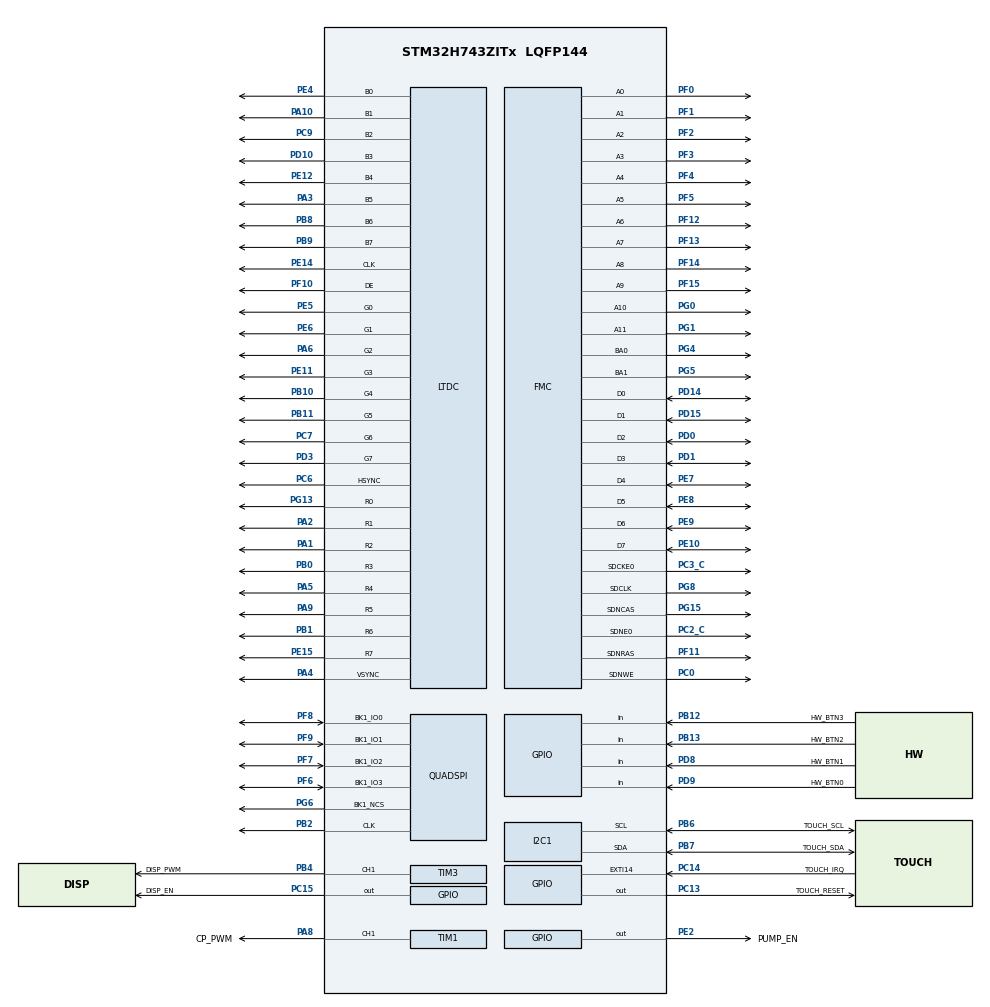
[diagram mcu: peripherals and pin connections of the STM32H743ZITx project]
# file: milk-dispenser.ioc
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CORTEX_M7.AccessPermission-Cortex_Memory_Protection_Unit_Region0_Settings=MPU_REGION_FULL_ACCESS
CORTEX_M7.AccessPermission-Cortex_Memory_Protection_Unit_Region1_Settings=MPU_REGION_FULL_ACCESS
CORTEX_M7.BaseAddress-Cortex_Memory_Protection_Unit_Region0_Settings=0x60000000
CORTEX_M7.BaseAddress-Cortex_Memory_Protection_Unit_Region1_Settings=0x30000000
CORTEX_M7.CPU_DCache=Enabled
CORTEX_M7.CPU_ICache=Enabled
CORTEX_M7.DisableExec-Cortex_Memory_Protection_Unit_Region0_Settings=MPU_INSTRUCTION_ACCESS_DISABLE
CORTEX_M7.DisableExec-Cortex_Memory_Protection_Unit_Region1_Settings=MPU_INSTRUCTION_ACCESS_DISABLE
CORTEX_M7.Enable-Cortex_Memory_Protection_Unit_Region0_Settings=MPU_REGION_ENABLE
CORTEX_M7.Enable-Cortex_Memory_Protection_Unit_Region1_Settings=MPU_REGION_ENABLE
CORTEX_M7.IsBufferable-Cortex_Memory_Protection_Unit_Region0_Settings=MPU_ACCESS_NOT_BUFFERABLE
CORTEX_M7.IsCacheable-Cortex_Memory_Protection_Unit_Region0_Settings=MPU_ACCESS_NOT_CACHEABLE
CORTEX_M7.IsCacheable-Cortex_Memory_Protection_Unit_Region1_Settings=MPU_ACCESS_CACHEABLE
CORTEX_M7.IsShareable-Cortex_Memory_Protection_Unit_Region0_Settings=MPU_ACCESS_SHAREABLE
CORTEX_M7.IsShareable-Cortex_Memory_Protection_Unit_Region1_Settings=MPU_ACCESS_NOT_SHAREABLE
CORTEX_M7.MPU_Control=MPU_PRIVILEGED_DEFAULT
CORTEX_M7.Size-Cortex_Memory_Protection_Unit_Region0_Settings=MPU_REGION_SIZE_16MB
CORTEX_M7.Size-Cortex_Memory_Protection_Unit_Region1_Settings=MPU_REGION_SIZE_128KB
DMA2D.ColorMode=DMA2D_OUTPUT_RGB565
FATFS._FS_LOCK=0
FATFS._FS_MINIMIZE=0
FATFS._MAX_SS=4096
FATFS._MIN_SS=4096
FATFS._USE_FASTSEEK=0
FATFS._USE_MKFS=0
FATFS._USE_STRFUNC=0
FMC.BankMapConfig=FMC_SWAPBMAP_SDRAM_SRAM
FMC.CASLatency1=FMC_SDRAM_CAS_LATENCY_2
FMC.ColumnBitsNumber1=FMC_SDRAM_COLUMN_BITS_NUM_10
FMC.ExitSelfRefreshDelay1=8
FMC.LoadToActiveDelay1=2
FMC.RCDDelay1=2
FMC.RPDelay1=2
FMC.RPDelay2=2
FMC.ReadBurst1=FMC_SDRAM_RBURST_ENABLE
FMC.ReadBurst2=FMC_SDRAM_RBURST_ENABLE
FMC.ReadPipeDelay1=FMC_SDRAM_RPIPE_DELAY_0
FMC.RowCycleDelay1=6
FMC.RowCycleDelay2=6
FMC.SDClockPeriod1=FMC_SDRAM_CLOCK_PERIOD_2
FMC.SelfRefreshTime1=5
FMC.WriteRecoveryTime1=3
I2C1.I2C_Fall_Time=14
I2C1.I2C_Rise_Time=14
I2C1.Speed=100
I2C1.Timing=0x108083B5
LTDC.ActiveW=800
LTDC.Alpha0_L0=0
LTDC.Alpha_L0=255
LTDC.BlendingFactor1_L0=LTDC_BLENDING_FACTOR1_PAxCA
LTDC.BlendingFactor2_L0=LTDC_BLENDING_FACTOR2_PAxCA
LTDC.Blue=0
LTDC.Green=0
LTDC.HBP=46
LTDC.HFP=4
LTDC.HSync=30
LTDC.ImageHeight_L0=480
LTDC.ImageWidth_L0=800
LTDC.Layers=0
LTDC.PCPolarity=LTDC_PCPOLARITY_IIPC
LTDC.PixelFormat_L0=LTDC_PIXEL_FORMAT_RGB565
LTDC.Red=0
LTDC.VBP=23
LTDC.VFP=22
LTDC.VSync=10
LTDC.WindowX0_L0=0
LTDC.WindowX1_L0=800
LTDC.WindowY0_L0=0
LTDC.WindowY1_L0=480
Mcu.Family=STM32H7
Mcu.Name=STM32H743ZITx
Mcu.Package=LQFP144
NVIC.EXTI15_10_IRQn=true\:2\:0\:true\:false\:true\:true\:true
NVIC.PriorityGroup=NVIC_PRIORITYGROUP_4
PA1.GPIO_Speed=GPIO_SPEED_FREQ_VERY_HIGH
PA1.Mode=RGB888
PA1.Signal=LTDC_R2
PA10.GPIO_Speed=GPIO_SPEED_FREQ_VERY_HIGH
PA10.Mode=RGB888
PA10.Signal=LTDC_B1
PA13\ (JTMS/SWDIO).Mode=Serial_Wire
PA13\ (JTMS/SWDIO).Signal=DEBUG_JTMS-SWDIO
PA14\ (JTCK/SWCLK).Mode=Serial_Wire
PA14\ (JTCK/SWCLK).Signal=DEBUG_JTCK-SWCLK
PA2.GPIO_Speed=GPIO_SPEED_FREQ_VERY_HIGH
PA2.Mode=RGB888
PA2.Signal=LTDC_R1
PA3.GPIO_Speed=GPIO_SPEED_FREQ_VERY_HIGH
PA3.Mode=RGB888
PA3.Signal=LTDC_B5
PA4.GPIO_Speed=GPIO_SPEED_FREQ_VERY_HIGH
PA4.Mode=RGB888
PA4.Signal=LTDC_VSYNC
PA5.GPIO_Speed=GPIO_SPEED_FREQ_VERY_HIGH
PA5.Mode=RGB888
PA5.Signal=LTDC_R4
PA6.GPIO_Speed=GPIO_SPEED_FREQ_VERY_HIGH
PA6.Mode=RGB888
PA6.Signal=LTDC_G2
PA8.GPIO_Label=CP_PWM
PA8.Signal=S_TIM1_CH1
PA9.GPIO_Speed=GPIO_SPEED_FREQ_VERY_HIGH
PA9.Mode=RGB888
PA9.Signal=LTDC_R5
PB0.GPIO_Speed=GPIO_SPEED_FREQ_VERY_HIGH
PB0.Mode=RGB888
PB0.Signal=LTDC_R3
PB1.GPIO_Speed=GPIO_SPEED_FREQ_VERY_HIGH
PB1.Mode=RGB888
PB1.Signal=LTDC_R6
PB10.GPIO_Speed=GPIO_SPEED_FREQ_VERY_HIGH
PB10.Mode=RGB888
PB10.Signal=LTDC_G4
PB11.GPIO_Speed=GPIO_SPEED_FREQ_VERY_HIGH
PB11.Mode=RGB888
PB11.Signal=LTDC_G5
PB12.GPIO_Label=HW_BTN3
PB12.GPIO_PuPd=GPIO_PULLUP
PB12.Signal=GPIO_Input
PB13.GPIO_Label=HW_BTN2
PB13.GPIO_PuPd=GPIO_PULLUP
PB13.Signal=GPIO_Input
PB2.GPIO_Speed=GPIO_SPEED_FREQ_VERY_HIGH
PB2.Mode=Single Bank 1
PB2.Signal=QUADSPI_CLK
PB4\ (NJTRST).GPIO_Label=DISP_PWM
PB4\ (NJTRST).GPIO_Speed=GPIO_SPEED_FREQ_HIGH
PB4\ (NJTRST).Signal=S_TIM3_CH1
PB6.GPIO_FM6=SYSCFG_PMCR_I2C_PB6_FMP
PB6.GPIO_Label=TOUCH_SCL
PB6.GPIO_PuPd=GPIO_PULLUP
PB6.GPIO_Speed=GPIO_SPEED_FREQ_VERY_HIGH
PB6.Mode=I2C
PB6.Signal=I2C1_SCL
PB7.GPIO_FM7=SYSCFG_PMCR_I2C_PB7_FMP
PB7.GPIO_Label=TOUCH_SDA
PB7.GPIO_PuPd=GPIO_PULLUP
PB7.GPIO_Speed=GPIO_SPEED_FREQ_VERY_HIGH
PB7.Mode=I2C
PB7.Signal=I2C1_SDA
PB8.GPIO_Speed=GPIO_SPEED_FREQ_VERY_HIGH
PB8.Mode=RGB888
PB8.Signal=LTDC_B6
PB9.GPIO_Speed=GPIO_SPEED_FREQ_VERY_HIGH
PB9.Mode=RGB888
PB9.Signal=LTDC_B7
PC0.Signal=FMC_SDNWE
PC13.GPIO_Label=TOUCH_RESET
PC13.GPIO_PuPd=GPIO_PULLUP
PC13.PinState=GPIO_PIN_RESET
PC13.Signal=GPIO_Output
PC14-OSC32_IN\ (OSC32_IN).GPIO_Label=TOUCH_IRQ
PC14-OSC32_IN\ (OSC32_IN).Signal=GPXTI14
PC15-OSC32_OUT\ (OSC32_OUT).GPIO_Label=DISP_EN
PC15-OSC32_OUT\ (OSC32_OUT).Signal=GPIO_Output
PC2_C.Mode=SdramChipSelect1_1
PC2_C.Signal=FMC_SDNE0
PC3_C.Mode=SdramChipSelect1_1
PC3_C.Signal=FMC_SDCKE0
PC6.GPIO_Speed=GPIO_SPEED_FREQ_VERY_HIGH
PC6.Mode=RGB888
PC6.Signal=LTDC_HSYNC
PC7.GPIO_Speed=GPIO_SPEED_FREQ_VERY_HIGH
PC7.Mode=RGB888
PC7.Signal=LTDC_G6
PC9.GPIO_Speed=GPIO_SPEED_FREQ_VERY_HIGH
PC9.Mode=RGB888
PC9.Signal=LTDC_B2
PD0.Signal=FMC_D2_DA2
PD1.Signal=FMC_D3_DA3
PD10.GPIO_Speed=GPIO_SPEED_FREQ_VERY_HIGH
PD10.Mode=RGB888
PD10.Signal=LTDC_B3
PD14.Signal=FMC_D0_DA0
PD15.Signal=FMC_D1_DA1
PD3.GPIO_Speed=GPIO_SPEED_FREQ_VERY_HIGH
PD3.Mode=RGB888
PD3.Signal=LTDC_G7
PD8.GPIO_Label=HW_BTN1
PD8.GPIO_PuPd=GPIO_PULLUP
PD8.Signal=GPIO_Input
PD9.GPIO_Label=HW_BTN0
PD9.GPIO_PuPd=GPIO_PULLUP
PD9.Signal=GPIO_Input
PE0.Signal=FMC_NBL0
PE10.Signal=FMC_D7_DA7
PE11.GPIO_Speed=GPIO_SPEED_FREQ_VERY_HIGH
PE11.Mode=RGB888
PE11.Signal=LTDC_G3
PE12.GPIO_Speed=GPIO_SPEED_FREQ_VERY_HIGH
PE12.Mode=RGB888
PE12.Signal=LTDC_B4
PE14.GPIO_Speed=GPIO_SPEED_FREQ_VERY_HIGH
PE14.Mode=RGB888
PE14.Signal=LTDC_CLK
PE15.GPIO_Speed=GPIO_SPEED_FREQ_VERY_HIGH
PE15.Mode=RGB888
PE15.Signal=LTDC_R7
PE2.GPIO_Label=PUMP_EN
PE2.Signal=GPIO_Output
PE4.GPIO_Speed=GPIO_SPEED_FREQ_VERY_HIGH
PE4.Mode=RGB888
PE4.Signal=LTDC_B0
PE5.GPIO_Speed=GPIO_SPEED_FREQ_VERY_HIGH
PE5.Mode=RGB888
PE5.Signal=LTDC_G0
PE6.GPIO_Speed=GPIO_SPEED_FREQ_VERY_HIGH
PE6.Mode=RGB888
PE6.Signal=LTDC_G1
PE7.Signal=FMC_D4_DA4
PE8.Signal=FMC_D5_DA5
PE9.Signal=FMC_D6_DA6
PF0.Signal=FMC_A0
PF1.Signal=FMC_A1
PF10.GPIO_Speed=GPIO_SPEED_FREQ_VERY_HIGH
PF10.Mode=RGB888
PF10.Signal=LTDC_DE
PF11.Signal=FMC_SDNRAS
PF12.Signal=FMC_A6
PF13.Signal=FMC_A7
PF14.Signal=FMC_A8
PF15.Signal=FMC_A9
PF2.Signal=FMC_A2
PF3.Signal=FMC_A3
PF4.Signal=FMC_A4
PF5.Signal=FMC_A5
PF6.GPIO_Speed=GPIO_SPEED_FREQ_VERY_HIGH
PF6.Mode=Single Bank 1
PF6.Signal=QUADSPI_BK1_IO3
PF7.GPIO_Speed=GPIO_SPEED_FREQ_VERY_HIGH
PF7.Mode=Single Bank 1
PF7.Signal=QUADSPI_BK1_IO2
PF8.GPIO_Speed=GPIO_SPEED_FREQ_VERY_HIGH
PF8.Mode=Single Bank 1
PF8.Signal=QUADSPI_BK1_IO0
PF9.GPIO_Speed=GPIO_SPEED_FREQ_VERY_HIGH
PF9.Mode=Single Bank 1
PF9.Signal=QUADSPI_BK1_IO1
PG0.Signal=FMC_A10
PG1.Signal=FMC_A11
PG13.GPIO_Speed=GPIO_SPEED_FREQ_VERY_HIGH
PG13.Mode=RGB888
PG13.Signal=LTDC_R0
PG15.Signal=FMC_SDNCAS
PG4.Signal=FMC_A14_BA0
PG5.Signal=FMC_A15_BA1
PG6.GPIO_Speed=GPIO_SPEED_FREQ_VERY_HIGH
PG6.Mode=Single Bank 1
PG6.Signal=QUADSPI_BK1_NCS
PG8.Signal=FMC_SDCLK
PH0-OSC_IN\ (PH0).Mode=HSE-External-Oscillator
PH0-OSC_IN\ (PH0).Signal=RCC_OSC_IN
PH1-OSC_OUT\ (PH1).Mode=HSE-External-Oscillator
PH1-OSC_OUT\ (PH1).Signal=RCC_OSC_OUT
ProjectManager.HeapSize=0x2000
ProjectManager.StackSize=0x4000
ProjectManager.TargetToolchain=STM32CubeIDE
QUADSPI.ChipSelectHighTime=QSPI_CS_HIGH_TIME_2_CYCLE
QUADSPI.ClockPrescaler=7
QUADSPI.FifoThreshold=5
QUADSPI.FlashSize=22
RCC.ADCFreq_Value=300000000
RCC.APB1Freq_Value=120000000
RCC.APB2Freq_Value=120000000
RCC.APB3Freq_Value=120000000
RCC.APB4Freq_Value=120000000
RCC.CKPERSourceSelection=RCC_CLKPSOURCE_CSI
RCC.CortexFreq_Value=480000000
RCC.D1PPRE=RCC_APB3_DIV2
RCC.D2PPRE1=RCC_APB1_DIV2
RCC.D2PPRE2=RCC_APB2_DIV2
RCC.D3PPRE=RCC_APB4_DIV2
RCC.DIVM1=2
RCC.DIVM2=3
RCC.DIVM3=3
RCC.DIVN1=64
RCC.DIVN2=60
RCC.DIVN3=20
RCC.DIVR2=3
RCC.DIVR3=10
RCC.FMCCLockSelection=RCC_FMCCLKSOURCE_PLL2
RCC.HCLKFreq_Value=240000000
RCC.HPRE=RCC_HCLK_DIV2
RCC.HSE_VALUE=30000000
RCC.I2C123CLockSelection=RCC_I2C123CLKSOURCE_HSI
RCC.PLL2FRACN=0
RCC.PLL3FRACN=0
RCC.PLLFRACN=0
RCC.PLLSourceVirtual=RCC_PLLSOURCE_HSE
RCC.ProductRev=revV
RCC.SYSCLKFreq_VALUE=480000000
RCC.SYSCLKSource=RCC_SYSCLKSOURCE_PLLCLK
RCC.USBCLockSelection=RCC_USBCLKSOURCE_HSI48
RCC.USBFreq_Value=48000000
SH.FMC_A0.0=FMC_A0,12b-sda1
SH.FMC_A1.0=FMC_A1,12b-sda1
SH.FMC_A10.0=FMC_A10,12b-sda1
SH.FMC_A11.0=FMC_A11,12b-sda1
SH.FMC_A14_BA0.0=FMC_BA0,FourSdramBanks1
SH.FMC_A15_BA1.0=FMC_BA1,FourSdramBanks1
SH.FMC_A2.0=FMC_A2,12b-sda1
SH.FMC_A3.0=FMC_A3,12b-sda1
SH.FMC_A4.0=FMC_A4,12b-sda1
SH.FMC_A5.0=FMC_A5,12b-sda1
SH.FMC_A6.0=FMC_A6,12b-sda1
SH.FMC_A7.0=FMC_A7,12b-sda1
SH.FMC_A8.0=FMC_A8,12b-sda1
SH.FMC_A9.0=FMC_A9,12b-sda1
SH.FMC_D0_DA0.0=FMC_D0,sd-8b-d1
SH.FMC_D1_DA1.0=FMC_D1,sd-8b-d1
SH.FMC_D2_DA2.0=FMC_D2,sd-8b-d1
SH.FMC_D3_DA3.0=FMC_D3,sd-8b-d1
SH.FMC_D4_DA4.0=FMC_D4,sd-8b-d1
SH.FMC_D5_DA5.0=FMC_D5,sd-8b-d1
SH.FMC_D6_DA6.0=FMC_D6,sd-8b-d1
SH.FMC_D7_DA7.0=FMC_D7,sd-8b-d1
SH.FMC_NBL0.0=FMC_NBL0
SH.FMC_SDCLK.0=FMC_SDCLK,12b-sda1
SH.FMC_SDNCAS.0=FMC_SDNCAS,12b-sda1
SH.FMC_SDNRAS.0=FMC_SDNRAS,12b-sda1
SH.FMC_SDNWE.0=FMC_SDNWE,12b-sda1
SH.S_TIM1_CH1.0=TIM1_CH1,PWM Generation1 CH1
SH.S_TIM3_CH1.0=TIM3_CH1,PWM Generation1 CH1
TIM1.AutoReloadPreload=TIM_AUTORELOAD_PRELOAD_DISABLE
TIM1.Channel-PWM\ Generation1\ CH1=TIM_CHANNEL_1
TIM1.Period=3000
TIM1.Prescaler=0
TIM1.Pulse-PWM\ Generation1\ CH1=1500
TIM3.Channel-PWM\ Generation1\ CH1=TIM_CHANNEL_1
TIM3.Period=1024
TIM3.Pulse-PWM\ Generation1\ CH1=922
VP_DMA2D_VS_DMA2D.Mode=DMA2D_Activate
VP_FATFS_VS_Generic.Mode=User_defined
VP_TIM1_VS_ClockSourceINT.Mode=Internal
VP_TIM3_VS_ClockSourceINT.Mode=Internal
board=custom

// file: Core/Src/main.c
/* USER CODE BEGIN Header */
/**
 ******************************************************************************
 * @file           : main.c
 * @brief          : Main program body
 ******************************************************************************
 * @attention
 *
 * <h2><center>&copy; Copyright (c) 2020 STMicroelectronics.
 * All rights reserved.</center></h2>
 *
 * This software component is licensed by ST under BSD 3-Clause license,
 * the "License"; You may not use this file except in compliance with the
 * License. You may obtain a copy of the License at:
 *                        opensource.org/licenses/BSD-3-Clause
 *
 ******************************************************************************
 */
/* USER CODE END Header */
#include "main.h"
#include "dma2d.h"
#include "fatfs.h"
#include "i2c.h"
#include "ltdc.h"
#include "quadspi.h"
#include "tim.h"
#include "gpio.h"
#include "fmc.h"

/* USER CODE BEGIN Includes */
#include <stdio.h>

#include "gt911.h"
#include "hw_buttons.h"
#include "interface.h"
#include "lvgl.h"
#include "pump.h"
#include "pump_power.h"
#include "sst26_flash.h"
#include "tft.h"

/* USER CODE END Includes */

void SystemClock_Config(void);
static void MPU_Config(void);

/* USER CODE BEGIN 0 */
volatile uint32_t time = 0;
volatile uint32_t period = 0;

static lv_color_t dbbuf[LV_HOR_RES_MAX * LV_VER_RES_MAX / 10];

/* USER CODE END 0 */

int main(void)
{
  /* USER CODE BEGIN 1 */
	SCB->VTOR = 0x08040000;
	__enable_irq();

	HAL_StatusTypeDef status;
  /* USER CODE END 1 */

  /* MPU Configuration--------------------------------------------------------*/
  MPU_Config();

  /* Enable I-Cache---------------------------------------------------------*/
  SCB_EnableICache();

  /* Enable D-Cache---------------------------------------------------------*/
  SCB_EnableDCache();

  /* MCU Configuration--------------------------------------------------------*/

  /* Reset of all peripherals, Initializes the Flash interface and the Systick. */
  HAL_Init();

  /* Configure the system clock */
  SystemClock_Config();

  /* Initialize all configured peripherals */
  MX_GPIO_Init();
  MX_LTDC_Init();
  MX_TIM3_Init();
  MX_FMC_Init();
  MX_I2C1_Init();
  MX_TIM1_Init();
  MX_QUADSPI_Init();
  MX_FATFS_Init();
  MX_DMA2D_Init();
  /* USER CODE BEGIN 2 */
	SST26_config.hqspi = &hqspi;
	SST26_config.timeout = 100;
	status = SST26_init();
	if (HAL_OK != status) {
		HAL_QSPI_GetError(&hqspi);
		HAL_QSPI_GetState(&hqspi);
		while (1)
			;
	}

	FATFS fat;
	f_mount(&fat, "", 1);

	pump_config.port = PUMP_EN_GPIO_Port;
	pump_config.pin = PUMP_EN_Pin;
	pump_init();

	pump_power_config.timer = &htim1;
	pump_power_config.channel = TIM_CHANNEL_1;
	pump_power_init();

	struct tTftFramebuffer framebuffer = TFT_init_framebuffer(&hltdc);

	HAL_GPIO_WritePin(DISP_EN_GPIO_Port, DISP_EN_Pin, GPIO_PIN_RESET);
	HAL_Delay(100);
	HAL_GPIO_WritePin(DISP_EN_GPIO_Port, DISP_EN_Pin, GPIO_PIN_SET);
	HAL_Delay(100);

	TFT_fill(framebuffer, LV_COLOR_WHITE);

	HAL_TIM_PWM_Start(&htim3, TIM_CHANNEL_1);
	for (uint32_t i = 1023; i > 0; i--) {
		TIM3->CCR1 = i;
		HAL_Delay(0);
	}
	TIM3->CCR1 = 0;
	HAL_TIM_PWM_Stop(&htim3, TIM_CHANNEL_1);

	if (GT911_Init() != HAL_OK) {
		while (1) {
			TFT_String(framebuffer, 100, 100, "Touch init error", LV_COLOR_RED,
			LV_COLOR_BLACK);
		}
	}

  /* USER CODE END 2 */

  /* Infinite loop */
  /* USER CODE BEGIN WHILE */
	printf("Initializing lv ... ");
	lv_init();
	printf("Done\n");

	printf("Initializing lv buffer ... ");
	static lv_disp_buf_t disp_buf;
	/*Declare a buffer for 1/10 screen size*/
	lv_disp_buf_init(&disp_buf, dbbuf, NULL,
			LV_HOR_RES_MAX * LV_VER_RES_MAX / 10); /*Initialize the display buffer*/
	printf("Done\n");

	printf("Creating display function ... ");
	void my_disp_flush(lv_disp_drv_t *disp, const lv_area_t *area,
			lv_color_t *color_p) {
		int32_t x;
		int32_t y;
		for (y = area->y1; y <= area->y2; y++) {
			for (x = area->x1; x <= area->x2; x++) {
				TFT_pixel(framebuffer, x, y, *color_p); /* Put a pixel to the display.*/
				color_p++;
			}
		}

		lv_disp_flush_ready(disp); /* Indicate you are ready with the flushing*/
	}
	printf("Done\n");

	printf("Initializing display driver ... ");
	lv_disp_drv_t disp_drv; /*Descriptor of a display driver*/
	lv_disp_drv_init(&disp_drv); /*Basic initialization*/
	disp_drv.flush_cb = my_disp_flush; /*Set your driver function*/
	disp_drv.buffer = &disp_buf; /*Assign the buffer to the display*/
	lv_disp_drv_register(&disp_drv); /*Finally register the driver*/
	printf("Done\n");

	printf("Creating touch function ... ");
	bool my_touchpad_read(struct _lv_indev_drv_t *indev_drv,
			lv_indev_data_t *data) {
		data->state =
				gt911.TouchCount > 0 ? LV_INDEV_STATE_PR : LV_INDEV_STATE_REL;

		if (data->state == LV_INDEV_STATE_PR) {
			data->point.x = gt911.Touches[0].point_x;
			data->point.y = gt911.Touches[0].point_y;
		}

		return (false); /*Return `false` because we are not buffering and no more data to read*/
	}
	printf("Done\n");

	printf("Initializing touch driver ... ");
	lv_indev_drv_t indev_drv; /*Descriptor of a input device driver*/
	lv_indev_drv_init(&indev_drv); /*Basic initialization*/
	indev_drv.type = LV_INDEV_TYPE_POINTER; /*Touch pad is a pointer-like device*/
	indev_drv.read_cb = my_touchpad_read; /*Set your driver function*/
	lv_indev_drv_register(&indev_drv); /*Finally register the driver*/
	printf("Done\n");

	// Add physical hardware buttons as fixed points on screen
	lv_indev_drv_init(&indev_hw_buttons_drv);
	indev_hw_buttons_drv.type = LV_INDEV_TYPE_BUTTON;
	indev_hw_buttons_drv.read_cb = hw_buttons_read;
	indev_hw_buttons = lv_indev_drv_register(&indev_hw_buttons_drv);
	const lv_point_t hw_buttons_points_array[] = { { 133, 240 }, { 400, 240 }, {
			666, 240 }, { 800 - 40, 40 } };
	lv_indev_set_button_points(indev_hw_buttons, hw_buttons_points_array);

	struct tAppConfig *config = AppConfig_get();

	create_main_interface(config);

	while (1) {
		uint32_t run_after = lv_task_handler();
		HAL_Delay(run_after);
    /* USER CODE END WHILE */

	}
}

void SystemClock_Config(void)
{
  RCC_OscInitTypeDef RCC_OscInitStruct = {0};
  RCC_ClkInitTypeDef RCC_ClkInitStruct = {0};

  /** Supply configuration update enable
  */
  HAL_PWREx_ConfigSupply(PWR_LDO_SUPPLY);
  /** Configure the main internal regulator output voltage
  */
  __HAL_PWR_VOLTAGESCALING_CONFIG(PWR_REGULATOR_VOLTAGE_SCALE0);

  while(!__HAL_PWR_GET_FLAG(PWR_FLAG_VOSRDY)) {}
  /** Macro to configure the PLL clock source
  */
  __HAL_RCC_PLL_PLLSOURCE_CONFIG(RCC_PLLSOURCE_HSE);
  /** Initializes the RCC Oscillators according to the specified parameters
  * in the RCC_OscInitTypeDef structure.
  */
  RCC_OscInitStruct.OscillatorType = RCC_OSCILLATORTYPE_HSI|RCC_OSCILLATORTYPE_HSE;
  RCC_OscInitStruct.HSEState = RCC_HSE_ON;
  RCC_OscInitStruct.HSIState = RCC_HSI_DIV1;
  RCC_OscInitStruct.HSICalibrationValue = RCC_HSICALIBRATION_DEFAULT;
  RCC_OscInitStruct.PLL.PLLState = RCC_PLL_ON;
  RCC_OscInitStruct.PLL.PLLSource = RCC_PLLSOURCE_HSE;
  RCC_OscInitStruct.PLL.PLLM = 2;
  RCC_OscInitStruct.PLL.PLLN = 64;
  RCC_OscInitStruct.PLL.PLLP = 2;
  RCC_OscInitStruct.PLL.PLLQ = 2;
  RCC_OscInitStruct.PLL.PLLR = 2;
  RCC_OscInitStruct.PLL.PLLRGE = RCC_PLL1VCIRANGE_3;
  RCC_OscInitStruct.PLL.PLLVCOSEL = RCC_PLL1VCOWIDE;
  RCC_OscInitStruct.PLL.PLLFRACN = 0;
  if (HAL_RCC_OscConfig(&RCC_OscInitStruct) != HAL_OK)
  {
    Error_Handler();
  }
  /** Initializes the CPU, AHB and APB buses clocks
  */
  RCC_ClkInitStruct.ClockType = RCC_CLOCKTYPE_HCLK|RCC_CLOCKTYPE_SYSCLK
                              |RCC_CLOCKTYPE_PCLK1|RCC_CLOCKTYPE_PCLK2
                              |RCC_CLOCKTYPE_D3PCLK1|RCC_CLOCKTYPE_D1PCLK1;
  RCC_ClkInitStruct.SYSCLKSource = RCC_SYSCLKSOURCE_PLLCLK;
  RCC_ClkInitStruct.SYSCLKDivider = RCC_SYSCLK_DIV1;
  RCC_ClkInitStruct.AHBCLKDivider = RCC_HCLK_DIV2;
  RCC_ClkInitStruct.APB3CLKDivider = RCC_APB3_DIV2;
  RCC_ClkInitStruct.APB1CLKDivider = RCC_APB1_DIV2;
  RCC_ClkInitStruct.APB2CLKDivider = RCC_APB2_DIV2;
  RCC_ClkInitStruct.APB4CLKDivider = RCC_APB4_DIV2;

  if (HAL_RCC_ClockConfig(&RCC_ClkInitStruct, FLASH_LATENCY_4) != HAL_OK)
  {
    Error_Handler();
  }
}

/* USER CODE BEGIN 4 */
void HAL_GPIO_EXTI_Callback(uint16_t GPIO_Pin) {
	if (GPIO_Pin == TOUCH_IRQ_Pin) {
		if (GT911_Scan(10) == HAL_ERROR) {
			GT911_Init();
			return;
		}
		GT911_CopyShadow();
	}
}

/* USER CODE END 4 */

/* MPU Configuration */

void MPU_Config(void)
{
  MPU_Region_InitTypeDef MPU_InitStruct = {0};

  /* Disables the MPU */
  HAL_MPU_Disable();
  /** Initializes and configures the Region and the memory to be protected
  */
  MPU_InitStruct.Enable = MPU_REGION_ENABLE;
  MPU_InitStruct.Number = MPU_REGION_NUMBER0;
  MPU_InitStruct.BaseAddress = 0x60000000;
  MPU_InitStruct.Size = MPU_REGION_SIZE_16MB;
  MPU_InitStruct.SubRegionDisable = 0x0;
  MPU_InitStruct.TypeExtField = MPU_TEX_LEVEL0;
  MPU_InitStruct.AccessPermission = MPU_REGION_FULL_ACCESS;
  MPU_InitStruct.DisableExec = MPU_INSTRUCTION_ACCESS_DISABLE;
  MPU_InitStruct.IsShareable = MPU_ACCESS_SHAREABLE;
  MPU_InitStruct.IsCacheable = MPU_ACCESS_NOT_CACHEABLE;
  MPU_InitStruct.IsBufferable = MPU_ACCESS_NOT_BUFFERABLE;

  HAL_MPU_ConfigRegion(&MPU_InitStruct);
  /** Initializes and configures the Region and the memory to be protected
  */
  MPU_InitStruct.Number = MPU_REGION_NUMBER1;
  MPU_InitStruct.BaseAddress = 0x30000000;
  MPU_InitStruct.Size = MPU_REGION_SIZE_128KB;
  MPU_InitStruct.IsShareable = MPU_ACCESS_NOT_SHAREABLE;
  MPU_InitStruct.IsCacheable = MPU_ACCESS_CACHEABLE;

  HAL_MPU_ConfigRegion(&MPU_InitStruct);
  /* Enables the MPU */
  HAL_MPU_Enable(MPU_PRIVILEGED_DEFAULT);

}

void Error_Handler(void)
{
  /* USER CODE BEGIN Error_Handler_Debug */
	/* User can add his own implementation to report the HAL error return state */
	__disable_irq();
	pump_off();
	while (1) {
	}
  /* USER CODE END Error_Handler_Debug */
}

/************************ (C) COPYRIGHT STMicroelectronics *****END OF FILE****/
